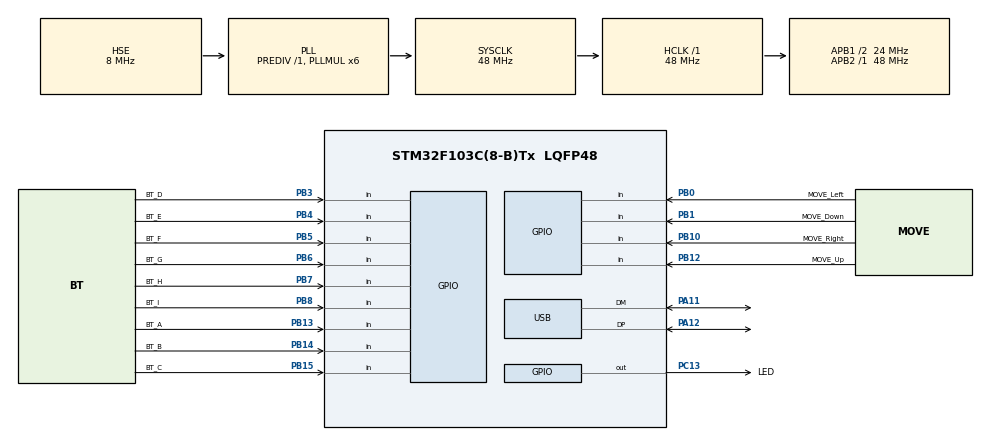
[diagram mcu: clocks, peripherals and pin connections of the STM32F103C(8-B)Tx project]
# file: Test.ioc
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Mcu.Family=STM32F1
Mcu.Name=STM32F103C(8-B)Tx
Mcu.Package=LQFP48
NVIC.PriorityGroup=NVIC_PRIORITYGROUP_4
NVIC.TIM2_IRQn=true\:0\:0\:false\:false\:true\:true\:true\:true
NVIC.USB_HP_CAN1_TX_IRQn=true\:0\:0\:false\:false\:true\:true\:true\:true
NVIC.USB_LP_CAN1_RX0_IRQn=true\:0\:0\:false\:false\:true\:true\:true\:true
PA11.Mode=Device
PA11.Signal=USB_DM
PA12.Mode=Device
PA12.Signal=USB_DP
PA13.Mode=Serial_Wire
PA13.Signal=SYS_JTMS-SWDIO
PA14.Mode=Serial_Wire
PA14.Signal=SYS_JTCK-SWCLK
PB0.GPIO_Label=MOVE_Left
PB0.GPIO_PuPd=GPIO_PULLUP
PB0.Signal=GPIO_Input
PB1.GPIO_Label=MOVE_Down
PB1.GPIO_PuPd=GPIO_PULLUP
PB1.Signal=GPIO_Input
PB10.GPIO_Label=MOVE_Right
PB10.GPIO_PuPd=GPIO_PULLUP
PB10.Signal=GPIO_Input
PB12.GPIO_Label=MOVE_Up
PB12.GPIO_PuPd=GPIO_PULLUP
PB12.Signal=GPIO_Input
PB13.GPIO_Label=BT_A
PB13.GPIO_PuPd=GPIO_PULLUP
PB13.Signal=GPIO_Input
PB14.GPIO_Label=BT_B
PB14.GPIO_PuPd=GPIO_PULLUP
PB14.Signal=GPIO_Input
PB15.GPIO_Label=BT_C
PB15.GPIO_PuPd=GPIO_PULLUP
PB15.Signal=GPIO_Input
PB3.GPIO_Label=BT_D
PB3.GPIO_PuPd=GPIO_PULLUP
PB3.Signal=GPIO_Input
PB4.GPIO_Label=BT_E
PB4.GPIO_PuPd=GPIO_PULLUP
PB4.Signal=GPIO_Input
PB5.GPIO_Label=BT_F
PB5.GPIO_PuPd=GPIO_PULLUP
PB5.Signal=GPIO_Input
PB6.GPIO_Label=BT_G
PB6.GPIO_PuPd=GPIO_PULLUP
PB6.Signal=GPIO_Input
PB7.GPIO_Label=BT_H
PB7.GPIO_PuPd=GPIO_PULLUP
PB7.Signal=GPIO_Input
PB8.GPIO_Label=BT_I
PB8.GPIO_PuPd=GPIO_PULLUP
PB8.Signal=GPIO_Input
PC13-TAMPER-RTC.GPIO_Label=LED
PC13-TAMPER-RTC.GPIO_PuPd=GPIO_NOPULL
PC13-TAMPER-RTC.PinState=GPIO_PIN_SET
PC13-TAMPER-RTC.Signal=GPIO_Output
PD0-OSC_IN.Mode=HSE-External-Oscillator
PD0-OSC_IN.Signal=RCC_OSC_IN
PD1-OSC_OUT.Mode=HSE-External-Oscillator
PD1-OSC_OUT.Signal=RCC_OSC_OUT
ProjectManager.HeapSize=0x200
ProjectManager.StackSize=0x400
ProjectManager.TargetToolchain=MDK-ARM V5.32
RCC.AHBFreq_Value=48000000
RCC.APB1CLKDivider=RCC_HCLK_DIV2
RCC.APB1Freq_Value=24000000
RCC.APB1TimFreq_Value=48000000
RCC.APB2Freq_Value=48000000
RCC.APB2TimFreq_Value=48000000
RCC.HCLKFreq_Value=48000000
RCC.PLLMUL=RCC_PLL_MUL6
RCC.SYSCLKFreq_VALUE=48000000
RCC.SYSCLKSource=RCC_SYSCLKSOURCE_PLLCLK
RCC.USBFreq_Value=48000000
TIM2.AutoReloadPreload=TIM_AUTORELOAD_PRELOAD_ENABLE
TIM2.Period=1000
TIM2.Prescaler=47
USB_DEVICE.CLASS_NAME_FS=CUSTOM_HID
USB_DEVICE.CUSTOM_HID_FS_BINTERVAL=0x1
USB_DEVICE.PRODUCT_STRING_CUSTOMHID_FS=FBL Hitbox
USB_DEVICE.USBD_CUSTOMHID_OUTREPORT_BUF_SIZE=8
USB_DEVICE.USBD_CUSTOM_HID_REPORT_DESC_SIZE=45
USB_DEVICE.VID=0x483
USB_DEVICE.VirtualMode=CustomHid
USB_DEVICE.VirtualModeFS=Custom_Hid_FS
VP_TIM2_VS_ClockSourceINT.Mode=Internal
VP_USB_DEVICE_VS_USB_DEVICE_CUSTOM_HID_FS.Mode=CUSTOM_HID_FS
board=custom

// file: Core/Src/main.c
/* USER CODE BEGIN Header */
/**
  ******************************************************************************
  * @file           : main.c
  * @brief          : Main program body
  ******************************************************************************
  * @attention
  *
  * Copyright (c) 2026 STMicroelectronics.
  * All rights reserved.
  *
  * This software is licensed under terms that can be found in the LICENSE file
  * in the root directory of this software component.
  * If no LICENSE file comes with this software, it is provided AS-IS.
  *
  ******************************************************************************
  */
/* USER CODE END Header */
#include "main.h"
#include "usb_device.h"

/* USER CODE BEGIN Includes */
#include "usbd_custom_hid_if.h"
#include "button.h"
#include "led.h"
/* USER CODE END Includes */

TIM_HandleTypeDef htim2;

/* USER CODE BEGIN PV */
/* 按键扫描节拍（1ms） */
static uint32_t s_buttonScanTick = 0u;
/* USER CODE END PV */

void SystemClock_Config(void);
static void MX_GPIO_Init(void);
static void MX_TIM2_Init(void);

int main(void)
{

  /* MCU Configuration--------------------------------------------------------*/

  /* Reset of all peripherals, Initializes the Flash interface and the Systick. */
  HAL_Init();

  /* USER CODE BEGIN Init */
  /* GC_Report_Buf 固定字段与按键状态机由 Button_Init() 初始化 */
  /* USER CODE END Init */

  /* Configure the system clock */
  SystemClock_Config();

  /* Initialize all configured peripherals */
  MX_GPIO_Init();
  MX_USB_DEVICE_Init();
  MX_TIM2_Init();
  /* USER CODE BEGIN 2 */
  /* 调试 LED：上电闪 3 次（约 0.6s），确认固件在运行且 LED 极性正确 */
  LED_Init();
  LED_Blink(3u, 80u, 120u);

  /* 初始化按键状态机与 GC_Report_Buf */
  Button_Init();
  s_buttonScanTick = HAL_GetTick();
  /* USER CODE END 2 */

  /* Infinite loop */
  while (1)
  {

    /* USER CODE BEGIN 3 */
    /* 1ms 扫描一次：状态机消抖，按下时零延迟打包 GC_Report_Buf 并通过 USB 发送 */
    if (HAL_GetTick() != s_buttonScanTick)
    {
      s_buttonScanTick = HAL_GetTick();
      Button_Scan();
    }
  }
  /* USER CODE END 3 */
}

void SystemClock_Config(void)
{
  RCC_OscInitTypeDef RCC_OscInitStruct = {0};
  RCC_ClkInitTypeDef RCC_ClkInitStruct = {0};
  RCC_PeriphCLKInitTypeDef PeriphClkInit = {0};

  /** Initializes the RCC Oscillators according to the specified parameters
  * in the RCC_OscInitTypeDef structure.
  */
  RCC_OscInitStruct.OscillatorType = RCC_OSCILLATORTYPE_HSE;
  RCC_OscInitStruct.HSEState = RCC_HSE_ON;
  RCC_OscInitStruct.HSEPredivValue = RCC_HSE_PREDIV_DIV1;
  RCC_OscInitStruct.HSIState = RCC_HSI_ON;
  RCC_OscInitStruct.PLL.PLLState = RCC_PLL_ON;
  RCC_OscInitStruct.PLL.PLLSource = RCC_PLLSOURCE_HSE;
  RCC_OscInitStruct.PLL.PLLMUL = RCC_PLL_MUL6;
  if (HAL_RCC_OscConfig(&RCC_OscInitStruct) != HAL_OK)
  {
    Error_Handler();
  }

  /** Initializes the CPU, AHB and APB buses clocks
  */
  RCC_ClkInitStruct.ClockType = RCC_CLOCKTYPE_HCLK|RCC_CLOCKTYPE_SYSCLK
                              |RCC_CLOCKTYPE_PCLK1|RCC_CLOCKTYPE_PCLK2;
  RCC_ClkInitStruct.SYSCLKSource = RCC_SYSCLKSOURCE_PLLCLK;
  RCC_ClkInitStruct.AHBCLKDivider = RCC_SYSCLK_DIV1;
  RCC_ClkInitStruct.APB1CLKDivider = RCC_HCLK_DIV2;
  RCC_ClkInitStruct.APB2CLKDivider = RCC_HCLK_DIV1;

  if (HAL_RCC_ClockConfig(&RCC_ClkInitStruct, FLASH_LATENCY_1) != HAL_OK)
  {
    Error_Handler();
  }
  PeriphClkInit.PeriphClockSelection = RCC_PERIPHCLK_USB;
  PeriphClkInit.UsbClockSelection = RCC_USBCLKSOURCE_PLL;
  if (HAL_RCCEx_PeriphCLKConfig(&PeriphClkInit) != HAL_OK)
  {
    Error_Handler();
  }
}

static void MX_TIM2_Init(void)
{

  TIM_ClockConfigTypeDef sClockSourceConfig = {0};
  TIM_MasterConfigTypeDef sMasterConfig = {0};

  htim2.Instance = TIM2;
  htim2.Init.Prescaler = 47;
  htim2.Init.CounterMode = TIM_COUNTERMODE_UP;
  htim2.Init.Period = 1000;
  htim2.Init.ClockDivision = TIM_CLOCKDIVISION_DIV1;
  htim2.Init.AutoReloadPreload = TIM_AUTORELOAD_PRELOAD_ENABLE;
  if (HAL_TIM_Base_Init(&htim2) != HAL_OK)
  {
    Error_Handler();
  }
  sClockSourceConfig.ClockSource = TIM_CLOCKSOURCE_INTERNAL;
  if (HAL_TIM_ConfigClockSource(&htim2, &sClockSourceConfig) != HAL_OK)
  {
    Error_Handler();
  }
  sMasterConfig.MasterOutputTrigger = TIM_TRGO_RESET;
  sMasterConfig.MasterSlaveMode = TIM_MASTERSLAVEMODE_DISABLE;
  if (HAL_TIMEx_MasterConfigSynchronization(&htim2, &sMasterConfig) != HAL_OK)
  {
    Error_Handler();
  }

}

static void MX_GPIO_Init(void)
{
  GPIO_InitTypeDef GPIO_InitStruct = {0};

  /* GPIO Ports Clock Enable */
  __HAL_RCC_GPIOC_CLK_ENABLE();
  __HAL_RCC_GPIOD_CLK_ENABLE();
  __HAL_RCC_GPIOB_CLK_ENABLE();
  __HAL_RCC_GPIOA_CLK_ENABLE();

  /*Configure GPIO pin Output Level */
  HAL_GPIO_WritePin(LED_GPIO_Port, LED_Pin, GPIO_PIN_SET);

  /*Configure GPIO pin : LED_Pin */
  GPIO_InitStruct.Pin = LED_Pin;
  GPIO_InitStruct.Mode = GPIO_MODE_OUTPUT_PP;
  GPIO_InitStruct.Pull = GPIO_NOPULL;
  GPIO_InitStruct.Speed = GPIO_SPEED_FREQ_LOW;
  HAL_GPIO_Init(LED_GPIO_Port, &GPIO_InitStruct);

  /*Configure GPIO pins : MOVE_Left_Pin MOVE_Down_Pin MOVE_Right_Pin MOVE_Up_Pin
                           BT_A_Pin BT_B_Pin BT_C_Pin BT_D_Pin
                           BT_E_Pin BT_F_Pin BT_G_Pin BT_H_Pin
                           BT_I_Pin */
  GPIO_InitStruct.Pin = MOVE_Left_Pin|MOVE_Down_Pin|MOVE_Right_Pin|MOVE_Up_Pin
                          |BT_A_Pin|BT_B_Pin|BT_C_Pin|BT_D_Pin
                          |BT_E_Pin|BT_F_Pin|BT_G_Pin|BT_H_Pin
                          |BT_I_Pin;
  GPIO_InitStruct.Mode = GPIO_MODE_INPUT;
  GPIO_InitStruct.Pull = GPIO_PULLUP;
  HAL_GPIO_Init(GPIOB, &GPIO_InitStruct);

}

void Error_Handler(void)
{
  __disable_irq();
  while (1)
  {
  }
}
